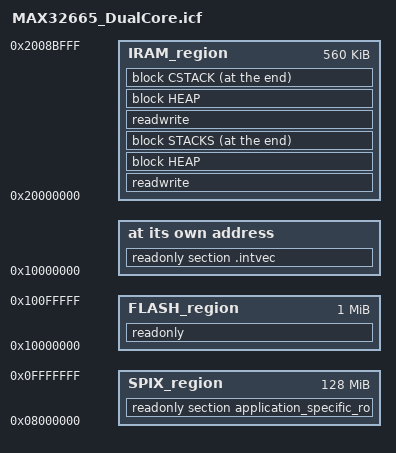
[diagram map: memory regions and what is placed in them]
/*###ICF### Section handled by ICF editor, don't touch! ****/
/*-Editor annotation file-*/
/* IcfEditorFile="$TOOLKIT_DIR$\config\ide\IcfEditor\cortex_v1_1.xml" */
/*-Specials-*/
define symbol __ICFEDIT_intvec_start__ = 0x10000000;
/*-Memory Regions-*/
define symbol __ICFEDIT_region_FLASH_start__ = 0x10000000;
define symbol __ICFEDIT_region_FLASH_end__   = 0x100FFFFF;
define symbol __ICFEDIT_region_SPIX_start__  = 0x08000000;
define symbol __ICFEDIT_region_SPIX_end__    = 0x0FFFFFFF;
define symbol __ICFEDIT_region_IRAM1_start__ = 0x20000000;
define symbol __ICFEDIT_region_IRAM1_end__   = 0x2008BFFF;
define symbol __DUAL_CORE = 1;

/*-Sizes-*/
define symbol __ICFEDIT_size_cstack__ = 0x1000;
define symbol __ICFEDIT_size_heap__   = 0x2000;
/**** End of ICF editor section. ###ICF###*/

define memory mem with size = 4G;
define region FLASH_region  =   mem:[from __ICFEDIT_region_FLASH_start__ to __ICFEDIT_region_FLASH_end__];
define region SPIX_region   =   mem:[from __ICFEDIT_region_SPIX_start__ to __ICFEDIT_region_SPIX_end__];
define region IRAM_region   =   mem:[from __ICFEDIT_region_IRAM1_start__ to __ICFEDIT_region_IRAM1_end__];

define block CSTACK    with alignment = 8, size = __ICFEDIT_size_cstack__   { };
define block HEAP      with alignment = 8, size = __ICFEDIT_size_heap__     { };

do not initialize  { section .noinit };
initialize by copy { readwrite };

if (isdefinedsymbol(__USE_DLIB_PERTHREAD))
{
  // Required in a multi-threaded application
  initialize by copy with packing = none { section __DLIB_PERTHREAD };
}

// Place the Core1 Stack at the top of RAM
// This will limit the size of the secondary stack
// but allow the primary core stack to expand as needed
if (isdefinedsymbol(__DUAL_CORE))
{
	define block CSTACKC1  with alignment = 8, size = __ICFEDIT_size_cstack__ { };
	define block STACKS with fixed order
	{
		block CSTACK,
		block CSTACKC1
	};
        place in IRAM_region  { readwrite, block HEAP};
		place at end of IRAM_region {block STACKS};
}

if (!isdefinedsymbol(__DUAL_CORE))
{
  place in IRAM_region  { readwrite, block HEAP};
  place at end of IRAM_region { block CSTACK};
}

place at address mem:__ICFEDIT_intvec_start__ { readonly section .intvec };

place in FLASH_region  { readonly };
place in SPIX_region  { readonly section application_specific_ro };
